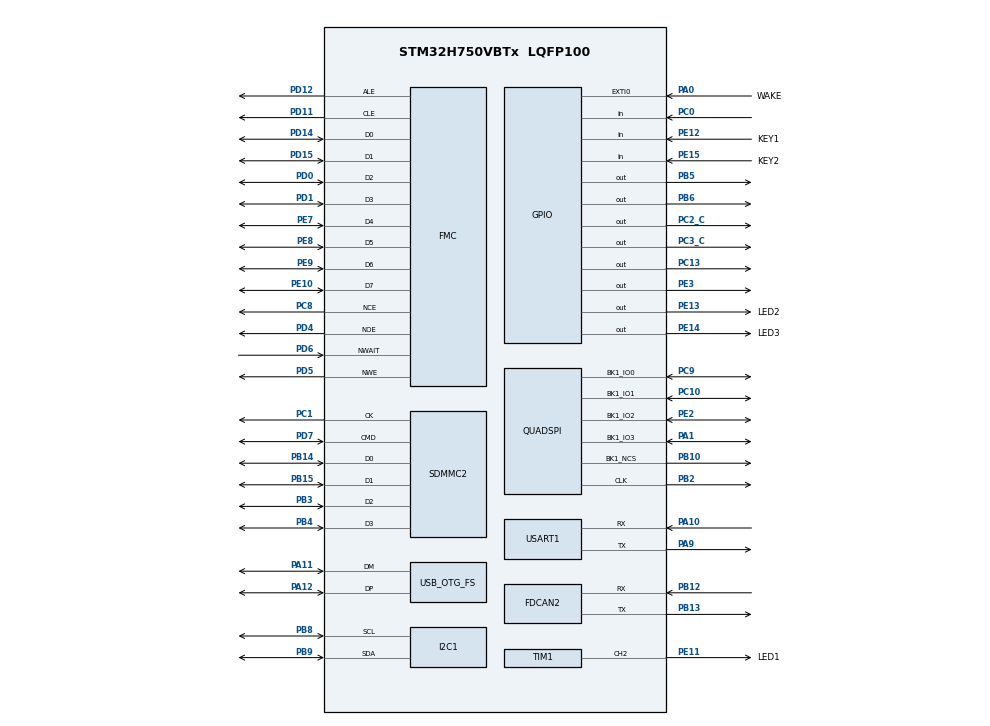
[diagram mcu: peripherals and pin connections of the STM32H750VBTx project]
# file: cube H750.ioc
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FDCAN2.AutoRetransmission=ENABLE
FDCAN2.DataSyncJumpWidth=8
FDCAN2.DataTimeSeg1=31
FDCAN2.DataTimeSeg2=8
FDCAN2.ExtFiltersNbr=1
FDCAN2.Mode=FDCAN_MODE_EXTERNAL_LOOPBACK
FDCAN2.NominalSyncJumpWidth=8
FDCAN2.NominalTimeSeg1=31
FDCAN2.NominalTimeSeg2=8
FDCAN2.ProtocolException=ENABLE
FDCAN2.RxBufferSize=FDCAN_DATA_BYTES_8
FDCAN2.RxBuffersNbr=1
FDCAN2.RxFifo0ElmtSize=FDCAN_DATA_BYTES_8
FDCAN2.RxFifo0ElmtsNbr=1
FDCAN2.RxFifo1ElmtSize=FDCAN_DATA_BYTES_8
FDCAN2.RxFifo1ElmtsNbr=2
FDCAN2.StdFiltersNbr=1
FDCAN2.TransmitPause=DISABLE
FDCAN2.TxBuffersNbr=1
FDCAN2.TxElmtSize=FDCAN_DATA_BYTES_8
FDCAN2.TxEventsNbr=2
FDCAN2.TxFifoQueueElmtsNbr=2
FDCAN2.TxFifoQueueMode=FDCAN_TX_FIFO_OPERATION
I2C1.Timing=0x307075B1
Mcu.Family=STM32H7
Mcu.Name=STM32H750VBTx
Mcu.Package=LQFP100
NVIC.EXTI0_IRQn=true\:0\:0\:false\:false\:true\:true\:true
NVIC.PriorityGroup=NVIC_PRIORITYGROUP_4
NVIC.TIM6_DAC_IRQn=true\:0\:0\:false\:false\:true\:false\:true
NVIC.TIM7_IRQn=true\:0\:0\:false\:false\:true\:true\:true
NVIC.TimeBase=TIM6_DAC_IRQn
NVIC.TimeBaseIP=TIM6
PA0.GPIO_Label=WAKE
PA0.GPIO_ModeDefaultEXTI=GPIO_MODE_IT_RISING
PA0.GPIO_PuPd=GPIO_NOPULL
PA0.Signal=GPXTI0
PA1.Mode=Single Bank 1
PA1.Signal=QUADSPI_BK1_IO3
PA10.Mode=Asynchronous
PA10.Signal=USART1_RX
PA11.Mode=Device_Only
PA11.Signal=USB_OTG_FS_DM
PA12.Mode=Device_Only
PA12.Signal=USB_OTG_FS_DP
PA13\ (JTMS/SWDIO).Mode=Serial_Wire
PA13\ (JTMS/SWDIO).Signal=DEBUG_JTMS-SWDIO
PA14\ (JTCK/SWCLK).Mode=Serial_Wire
PA14\ (JTCK/SWCLK).Signal=DEBUG_JTCK-SWCLK
PA9.Mode=Asynchronous
PA9.Signal=USART1_TX
PB10.Mode=Single Bank 1
PB10.Signal=QUADSPI_BK1_NCS
PB12.Mode=FDCANFD
PB12.Signal=FDCAN2_RX
PB13.Mode=FDCANFD
PB13.Signal=FDCAN2_TX
PB14.Mode=SD_4_bits_Wide_bus
PB14.Signal=SDMMC2_D0
PB15.Mode=SD_4_bits_Wide_bus
PB15.Signal=SDMMC2_D1
PB2.Mode=Single Bank 1
PB2.Signal=QUADSPI_CLK
PB3\ (JTDO/TRACESWO).Mode=SD_4_bits_Wide_bus
PB3\ (JTDO/TRACESWO).Signal=SDMMC2_D2
PB4\ (NJTRST).Mode=SD_4_bits_Wide_bus
PB4\ (NJTRST).Signal=SDMMC2_D3
PB5.GPIO_ModeDefaultOutputPP=GPIO_MODE_OUTPUT_PP
PB5.GPIO_PuPd=GPIO_NOPULL
PB5.GPIO_Speed=GPIO_SPEED_FREQ_LOW
PB5.PinState=GPIO_PIN_RESET
PB5.Signal=GPIO_Output
PB6.GPIO_FM6=__NULL
PB6.GPIO_ModeDefaultOutputPP=GPIO_MODE_OUTPUT_PP
PB6.GPIO_PuPd=GPIO_NOPULL
PB6.GPIO_Speed=GPIO_SPEED_FREQ_LOW
PB6.PinState=GPIO_PIN_RESET
PB6.Signal=GPIO_Output
PB8.Mode=I2C
PB8.Signal=I2C1_SCL
PB9.Mode=I2C
PB9.Signal=I2C1_SDA
PC0.GPIO_Mode=GPIO_MODE_INPUT
PC0.GPIO_PuPd=GPIO_NOPULL
PC0.Signal=GPIO_Input
PC1.Mode=SD_4_bits_Wide_bus
PC1.Signal=SDMMC2_CK
PC10.Mode=Single Bank 1
PC10.Signal=QUADSPI_BK1_IO1
PC13.GPIO_ModeDefaultOutputPP=GPIO_MODE_OUTPUT_PP
PC13.GPIO_PuPd=GPIO_NOPULL
PC13.GPIO_Speed=GPIO_SPEED_FREQ_LOW
PC13.PinState=GPIO_PIN_RESET
PC13.Signal=GPIO_Output
PC2_C.GPIO_ModeDefaultOutputPP=GPIO_MODE_OUTPUT_PP
PC2_C.GPIO_PuPd=GPIO_NOPULL
PC2_C.GPIO_Speed=GPIO_SPEED_FREQ_LOW
PC2_C.PinState=GPIO_PIN_RESET
PC2_C.Signal=GPIO_Output
PC3_C.GPIO_ModeDefaultOutputPP=GPIO_MODE_OUTPUT_PP
PC3_C.GPIO_PuPd=GPIO_NOPULL
PC3_C.GPIO_Speed=GPIO_SPEED_FREQ_LOW
PC3_C.PinState=GPIO_PIN_RESET
PC3_C.Signal=GPIO_Output
PC8.Mode=NandChipSelect3_1
PC8.Signal=FMC_NCE
PC9.Mode=Single Bank 1
PC9.Signal=QUADSPI_BK1_IO0
PD0.Signal=FMC_D2_DA2
PD1.Signal=FMC_D3_DA3
PD11.Signal=FMC_A16_CLE
PD12.Signal=FMC_A17_ALE
PD14.Signal=FMC_D0_DA0
PD15.Signal=FMC_D1_DA1
PD4.Signal=FMC_NOE
PD5.Signal=FMC_NWE
PD6.Signal=FMC_NWAIT
PD7.Mode=SD_4_bits_Wide_bus
PD7.Signal=SDMMC2_CMD
PE10.Signal=FMC_D7_DA7
PE11.GPIO_Label=LED1
PE11.GPIO_ModeDefaultPP=GPIO_MODE_AF_PP
PE11.GPIO_PuPd=GPIO_NOPULL
PE11.GPIO_Speed=GPIO_SPEED_FREQ_LOW
PE11.Signal=S_TIM1_CH2
PE12.GPIO_Label=KEY1
PE12.GPIO_Mode=GPIO_MODE_INPUT
PE12.GPIO_PuPd=GPIO_NOPULL
PE12.Signal=GPIO_Input
PE13.GPIO_Label=LED2
PE13.GPIO_ModeDefaultOutputPP=GPIO_MODE_OUTPUT_PP
PE13.GPIO_PuPd=GPIO_NOPULL
PE13.GPIO_Speed=GPIO_SPEED_FREQ_LOW
PE13.PinState=GPIO_PIN_RESET
PE13.Signal=GPIO_Output
PE14.GPIO_Label=LED3
PE14.GPIO_ModeDefaultOutputPP=GPIO_MODE_OUTPUT_PP
PE14.GPIO_PuPd=GPIO_NOPULL
PE14.GPIO_Speed=GPIO_SPEED_FREQ_LOW
PE14.PinState=GPIO_PIN_RESET
PE14.Signal=GPIO_Output
PE15.GPIO_Label=KEY2
PE15.GPIO_Mode=GPIO_MODE_INPUT
PE15.GPIO_PuPd=GPIO_NOPULL
PE15.Signal=GPIO_Input
PE2.Mode=Single Bank 1
PE2.Signal=QUADSPI_BK1_IO2
PE3.GPIO_ModeDefaultOutputPP=GPIO_MODE_OUTPUT_PP
PE3.GPIO_PuPd=GPIO_NOPULL
PE3.GPIO_Speed=GPIO_SPEED_FREQ_LOW
PE3.PinState=GPIO_PIN_RESET
PE3.Signal=GPIO_Output
PE7.Signal=FMC_D4_DA4
PE8.Signal=FMC_D5_DA5
PE9.Signal=FMC_D6_DA6
PH0-OSC_IN\ (PH0).Mode=HSE-External-Oscillator
PH0-OSC_IN\ (PH0).Signal=RCC_OSC_IN
PH1-OSC_OUT\ (PH1).Mode=HSE-External-Oscillator
PH1-OSC_OUT\ (PH1).Signal=RCC_OSC_OUT
ProjectManager.HeapSize=0x200
ProjectManager.StackSize=0x400
ProjectManager.TargetToolchain=MDK-ARM V5
RCC.ADCFreq_Value=15000000
RCC.APB1Freq_Value=120000000
RCC.APB2Freq_Value=120000000
RCC.APB3Freq_Value=120000000
RCC.APB4Freq_Value=120000000
RCC.CKPERSourceSelection=RCC_CLKPSOURCE_HSE
RCC.CortexFreq_Value=480000000
RCC.D1PPRE=RCC_APB3_DIV2
RCC.D2PPRE1=RCC_APB1_DIV2
RCC.D2PPRE2=RCC_APB2_DIV2
RCC.D3PPRE=RCC_APB4_DIV2
RCC.DIVM1=1
RCC.DIVM3=1
RCC.DIVN1=120
RCC.DIVN2=120
RCC.DIVN3=160
RCC.DIVQ1=24
RCC.DIVQ3=4
RCC.DIVR1=4
RCC.DIVR2=1
RCC.DIVR3=8
RCC.FLatency=FLASH_LATENCY_7
RCC.HCLKFreq_Value=240000000
RCC.HPRE=RCC_HCLK_DIV2
RCC.HSE_VALUE=8000000
RCC.PLL2FRACN=0
RCC.PLL3FRACN=0
RCC.PLLFRACN=0
RCC.PLLSourceVirtual=RCC_PLLSOURCE_HSE
RCC.PWR_Regulator_Voltage_Scale=PWR_REGULATOR_VOLTAGE_SCALE0
RCC.SYSCLKFreq_VALUE=480000000
RCC.SYSCLKSource=RCC_SYSCLKSOURCE_PLLCLK
RCC.Tim1Mul=1
RCC.Tim2Mul=1
RCC.USBCLockSelection=RCC_USBCLKSOURCE_HSI48
RCC.USBFreq_Value=48000000
SH.FMC_A16_CLE.0=FMC_CLE,8b-dmux1
SH.FMC_A17_ALE.0=FMC_ALE,8b-dmux1
SH.FMC_D0_DA0.0=FMC_D0,8b-dmux1
SH.FMC_D1_DA1.0=FMC_D1,8b-dmux1
SH.FMC_D2_DA2.0=FMC_D2,8b-dmux1
SH.FMC_D3_DA3.0=FMC_D3,8b-dmux1
SH.FMC_D4_DA4.0=FMC_D4,8b-dmux1
SH.FMC_D5_DA5.0=FMC_D5,8b-dmux1
SH.FMC_D6_DA6.0=FMC_D6,8b-dmux1
SH.FMC_D7_DA7.0=FMC_D7,8b-dmux1
SH.FMC_NOE.0=FMC_NOE,8b-dmux1
SH.FMC_NWAIT.0=FMC_NWAIT,Wait1
SH.FMC_NWE.0=FMC_NWE,8b-dmux1
SH.S_TIM1_CH2.0=TIM1_CH2,PWM Generation2 CH2
TIM1.Channel-PWM\ Generation2\ CH2=TIM_CHANNEL_2
TIM1.ClockDivision=TIM_CLOCKDIVISION_DIV1
TIM1.Period=2000-1
TIM1.Prescaler=1200-1
TIM17.AutoReloadPreload=TIM_AUTORELOAD_PRELOAD_DISABLE
TIM17.Period=1000-1
TIM17.Prescaler=24000-1
TIM7.AutoReloadPreload=TIM_AUTORELOAD_PRELOAD_DISABLE
TIM7.Period=10000-1
TIM7.Prescaler=12000-1
USART1.VirtualMode-Asynchronous=VM_ASYNC
USB_OTG_FS.VirtualMode=Device_Only
VP_SYS_VS_tim6.Mode=TIM6
VP_TIM17_VS_ClockSourceINT.Mode=Enable_Timer
VP_TIM7_VS_ClockSourceINT.Mode=Enable_Timer
board=custom

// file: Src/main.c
/* USER CODE BEGIN Header */
/**
  ******************************************************************************
  * @file           : main.c
  * @brief          : Main program body
  ******************************************************************************
  * @attention
  *
  * <h2><center>&copy; Copyright (c) 2019 STMicroelectronics.
  * All rights reserved.</center></h2>
  *
  * This software component is licensed by ST under BSD 3-Clause license,
  * the "License"; You may not use this file except in compliance with the
  * License. You may obtain a copy of the License at:
  *                        opensource.org/licenses/BSD-3-Clause
  *
  ******************************************************************************
  */
/* USER CODE END Header */

#include "main.h"
#include "fdcan.h"
#include "i2c.h"
#include "quadspi.h"
#include "sdmmc.h"
#include "tim.h"
#include "usart.h"
#include "usb_otg.h"
#include "gpio.h"
#include "fmc.h"

/* USER CODE BEGIN Includes */
void user_pwm_setvalue(uint16_t value);
/* USER CODE END Includes */

/* USER CODE BEGIN PV */
int DEBUG1 = 0;
uint16_t step , pwm_value;
/* USER CODE END PV */

void SystemClock_Config(void);

int main(void)
{

  /* MCU Configuration--------------------------------------------------------*/

  /* Reset of all peripherals, Initializes the Flash interface and the Systick. */
  HAL_Init();

  /* Configure the system clock */
  SystemClock_Config();

  /* Initialize all configured peripherals */
  MX_GPIO_Init();
  MX_USB_OTG_FS_PCD_Init();
  MX_USART1_UART_Init();
  MX_QUADSPI_Init();
  MX_I2C1_Init();
  MX_FMC_Init();
  MX_SDMMC2_SD_Init();
  MX_FDCAN2_Init();
  MX_TIM17_Init();
  MX_TIM7_Init();
  MX_TIM1_Init();
  /* USER CODE BEGIN 2 */

  /*##-1- Start the TIM Base generation in interrupt mode ####################*/
  HAL_TIM_Base_Start_IT(&htim7);
   //HAL_TIM_PWM_Start(&htim1, TIM_CHANNEL_2);
//
  /* USER CODE END 2 */

  /* Infinite loop */
  /* USER CODE BEGIN WHILE */

  while (1)
  {
      DEBUG1++;
      HAL_Delay(1000);
    /* USER CODE END WHILE */

    /* USER CODE BEGIN 3 */

//  HAL_Delay(100);
//  if(pwm_value == 0) step = 100;
//  if(pwm_value == 2000) step = -100;
//  pwm_value += step;
//  user_pwm_setvalue( pwm_value);
  }
  /* USER CODE END 3 */
}

void SystemClock_Config(void)
{
  RCC_OscInitTypeDef RCC_OscInitStruct = {0};
  RCC_ClkInitTypeDef RCC_ClkInitStruct = {0};
  RCC_PeriphCLKInitTypeDef PeriphClkInitStruct = {0};

  /** Supply configuration update enable
  */
  HAL_PWREx_ConfigSupply(PWR_LDO_SUPPLY);
  /** Configure the main internal regulator output voltage
  */
  __HAL_PWR_VOLTAGESCALING_CONFIG(PWR_REGULATOR_VOLTAGE_SCALE0);

  while(!__HAL_PWR_GET_FLAG(PWR_FLAG_VOSRDY)) {}
  /** Initializes the CPU, AHB and APB busses clocks
  */
  RCC_OscInitStruct.OscillatorType = RCC_OSCILLATORTYPE_HSI48|RCC_OSCILLATORTYPE_HSE;
  RCC_OscInitStruct.HSEState = RCC_HSE_ON;
  RCC_OscInitStruct.HSI48State = RCC_HSI48_ON;
  RCC_OscInitStruct.PLL.PLLState = RCC_PLL_ON;
  RCC_OscInitStruct.PLL.PLLSource = RCC_PLLSOURCE_HSE;
  RCC_OscInitStruct.PLL.PLLM = 1;
  RCC_OscInitStruct.PLL.PLLN = 120;
  RCC_OscInitStruct.PLL.PLLP = 2;
  RCC_OscInitStruct.PLL.PLLQ = 24;
  RCC_OscInitStruct.PLL.PLLR = 4;
  RCC_OscInitStruct.PLL.PLLRGE = RCC_PLL1VCIRANGE_3;
  RCC_OscInitStruct.PLL.PLLVCOSEL = RCC_PLL1VCOWIDE;
  RCC_OscInitStruct.PLL.PLLFRACN = 0;
  if (HAL_RCC_OscConfig(&RCC_OscInitStruct) != HAL_OK)
  {
    Error_Handler();
  }
  /** Initializes the CPU, AHB and APB busses clocks
  */
  RCC_ClkInitStruct.ClockType = RCC_CLOCKTYPE_HCLK|RCC_CLOCKTYPE_SYSCLK
                              |RCC_CLOCKTYPE_PCLK1|RCC_CLOCKTYPE_PCLK2
                              |RCC_CLOCKTYPE_D3PCLK1|RCC_CLOCKTYPE_D1PCLK1;
  RCC_ClkInitStruct.SYSCLKSource = RCC_SYSCLKSOURCE_PLLCLK;
  RCC_ClkInitStruct.SYSCLKDivider = RCC_SYSCLK_DIV1;
  RCC_ClkInitStruct.AHBCLKDivider = RCC_HCLK_DIV2;
  RCC_ClkInitStruct.APB3CLKDivider = RCC_APB3_DIV2;
  RCC_ClkInitStruct.APB1CLKDivider = RCC_APB1_DIV2;
  RCC_ClkInitStruct.APB2CLKDivider = RCC_APB2_DIV2;
  RCC_ClkInitStruct.APB4CLKDivider = RCC_APB4_DIV2;

  if (HAL_RCC_ClockConfig(&RCC_ClkInitStruct, FLASH_LATENCY_7) != HAL_OK)
  {
    Error_Handler();
  }
  PeriphClkInitStruct.PeriphClockSelection = RCC_PERIPHCLK_FDCAN|RCC_PERIPHCLK_USART1
                              |RCC_PERIPHCLK_SDMMC|RCC_PERIPHCLK_I2C1
                              |RCC_PERIPHCLK_USB|RCC_PERIPHCLK_QSPI
                              |RCC_PERIPHCLK_FMC;
  PeriphClkInitStruct.FmcClockSelection = RCC_FMCCLKSOURCE_D1HCLK;
  PeriphClkInitStruct.QspiClockSelection = RCC_QSPICLKSOURCE_D1HCLK;
  PeriphClkInitStruct.SdmmcClockSelection = RCC_SDMMCCLKSOURCE_PLL;
  PeriphClkInitStruct.FdcanClockSelection = RCC_FDCANCLKSOURCE_PLL;
  PeriphClkInitStruct.Usart16ClockSelection = RCC_USART16CLKSOURCE_D2PCLK2;
  PeriphClkInitStruct.I2c123ClockSelection = RCC_I2C123CLKSOURCE_D2PCLK1;
  PeriphClkInitStruct.UsbClockSelection = RCC_USBCLKSOURCE_HSI48;
  if (HAL_RCCEx_PeriphCLKConfig(&PeriphClkInitStruct) != HAL_OK)
  {
    Error_Handler();
  }
  /** Enable USB Voltage detector
  */
  HAL_PWREx_EnableUSBVoltageDetector();
}

/* USER CODE BEGIN 4 */

/**
  * @brief EXTI line detection callbacks
  * @param GPIO_Pin: Specifies the pins connected EXTI line
  * @retval None
  */
//void HAL_GPIO_EXTI_Callback(uint16_t GPIO_Pin)
//{
//  if(GPIO_Pin == GPIO_PIN_0)
//  {
//    /* Toggle LED1 */
//    BSP_LED_Toggle(LED1);
//  }
//}

//void user_pwm_setvalue(uint16_t value)
//{
//    TIM_OC_InitTypeDef sConfigOC;
//
//    sConfigOC.OCMode = TIM_OCMODE_PWM1;
//    sConfigOC.Pulse = value;
//    sConfigOC.OCPolarity = TIM_OCPOLARITY_HIGH;
//    sConfigOC.OCFastMode = TIM_OCFAST_DISABLE;
//    HAL_TIM_PWM_ConfigChannel(&htim1, &sConfigOC, TIM_CHANNEL_2);
//    HAL_TIM_PWM_Start(&htim1, TIM_CHANNEL_2);
//}

/* USER CODE END 4 */

void HAL_TIM_PeriodElapsedCallback(TIM_HandleTypeDef *htim)
{
    if (htim->Instance == TIM7)
    {
        /* Toggle LED */
        BSP_LED_Toggle(LED1);
        BSP_LED_Toggle(LED2);
        BSP_LED_Toggle(LED3);
    }
  if (htim->Instance == TIM6) {
    HAL_IncTick();
  }
}

void Error_Handler(void)
{
}

/************************ (C) COPYRIGHT STMicroelectronics *****END OF FILE****/
